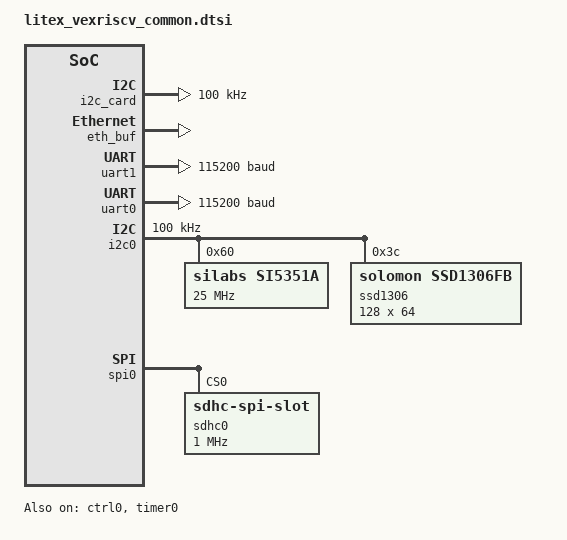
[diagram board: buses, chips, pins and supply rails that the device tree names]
/*
 * AES67 LiteX VexRiscv — common device-tree fragment.
 *
 * Shared across all `litex_vexriscv_<target>` board variants. Contains the
 * hand-written peripheral definitions (I2C devices, UART1 for the display
 * controller, SPI/SDHC, eth_buf IRQ dispatch node, disables, chosen) that
 * are identical for every target. Per-target register addresses live in
 * the auto-generated `<target>_csr.dtsi`, which the variant's `.dts`
 * includes alongside this file.
 */

#include <zephyr/dt-bindings/i2c/i2c.h>

/ {
	chosen {
		zephyr,console = &uart0;
		zephyr,shell-uart = &uart0;
		zephyr,sram = &ram0;
	};
};

/* ---- SoC controller (ctrl) ---- */
&ctrl0 {
	reg-names = "reset",
		    "scratch",
		    "bus_errors";
	status = "okay";
};

/* ---- UART 0 (console) ---- */
&uart0 {
	reg-names = "rxtx",
		    "txfull",
		    "rxempty",
		    "ev_status",
		    "ev_pending",
		    "ev_enable",
		    "txempty",
		    "rxfull";
	interrupts = <0 1>;
	current-speed = <115200>;
	status = "okay";
};

/* ---- Timer 0 ---- */
&timer0 {
	reg-names = "load",
		    "reload",
		    "en",
		    "update_value",
		    "value",
		    "ev_status",
		    "ev_pending",
		    "ev_enable",
		    "uptime_latch",
		    "uptime_cycles";
	interrupts = <1 1>;
	status = "okay";
};

/* ---- I2C 0: Display (SSD1306) + PLL (Si5351A) ---- */
&i2c0 {
	reg-names = "write", "read";
	clock-frequency = <I2C_BITRATE_STANDARD>;
	status = "okay";

	si5351a: si5351a@60 {
		compatible = "silabs,si5351a";
		reg = <0x60>;
		clock-frequency = <25000000>;
		silabs,xtal-load-pf = <10>;
	};

	ssd1306: ssd1306@3c {
		compatible = "solomon,ssd1306fb";
		reg = <0x3c>;
		width = <128>;
		height = <64>;
		segment-offset = <0>;
		page-offset = <0>;
		display-offset = <0>;
		multiplex-ratio = <63>;
		segment-remap;
		com-invdir;
		prechargep = <0x22>;
	};
};

/* ---- I2C 1 (litex,litei2c): disable the default DTSI instance ---- */
&i2c1 {
	status = "disabled";
};

/* Hardware I2C for the AD/DA card controller. Reg addresses come from
 * <target>_csr.dtsi via a &i2c_card override there. */
/ {
	soc {
		i2c_card: i2c2: i2c@f0002800 {
			compatible = "litex,litei2c";
			reg-names = "phy_speed_mode",
				    "master_active",
				    "master_settings",
				    "master_addr",
				    "master_rxtx",
				    "master_status";
			clock-frequency = <I2C_BITRATE_STANDARD>;
			#address-cells = <1>;
			#size-cells = <0>;
			status = "okay";
		};
	};
};

/* ---- SPI 0: SD card ---- */
&spi0 {
	reg-names = "control",
		    "status",
		    "mosi",
		    "miso",
		    "cs",
		    "loopback";
	status = "okay";
	#address-cells = <1>;
	#size-cells = <0>;

	sdhc0: sdhc@0 {
		compatible = "zephyr,sdhc-spi-slot";
		reg = <0>;
		status = "okay";
		spi-max-frequency = <1000000>;
		power-delay-ms = <1000>;
		mmc {
			compatible = "zephyr,sdmmc-disk";
			disk-name = "SD";
			status = "okay";
		};
	};
};

/* ---- EthPacketBuffer EventManager (IRQ dispatch node) ----
 * The eth_buf peripheral is instantiated in C (not DT-bound) but the LiteX
 * interrupt controller dispatches IRQs only for DT nodes picked up by
 * DT_FOREACH_STATUS_OKAY_NODE. Without this node IRQ 3 would storm. */
/ {
	soc {
		eth_buf: eth_buf@f0001000 {
			compatible = "litex,eth-buf-event";
			reg = <0xf0001000 0x20>;
			interrupt-parent = <&intc0>;
			interrupts = <3 1>;
			status = "okay";
		};
	};
};

/* ---- Peripherals absent from our SoC ---- */
&eth0     { status = "disabled"; };
&mdio0    { status = "disabled"; };
&dna0     { status = "disabled"; };
&prbs0    { status = "disabled"; };
&wdt0     { status = "disabled"; };
&clock0   { status = "disabled"; };
&gpio_out { status = "disabled"; };
&gpio_in  { status = "disabled"; };
&i2s_rx   { status = "disabled"; };
&i2s_tx   { status = "disabled"; };
&spi1     { status = "disabled"; };
&pwm0     { status = "disabled"; };

/* ---- Chosen display ---- */
/ {
	chosen {
		zephyr,display = &ssd1306;
	};
};

/* ---- UART 1: display-controller LED UART. Reg override in <target>_csr.dtsi ---- */
/ {
	soc {
		uart1: serial@f0006000 {
			compatible = "litex,uart";
			interrupt-parent = <&intc0>;
			interrupts = <2 1>;
			reg-names = "rxtx",
				    "txfull",
				    "rxempty",
				    "ev_status",
				    "ev_pending",
				    "ev_enable",
				    "txempty",
				    "rxfull";
			current-speed = <115200>;
			status = "okay";
		};
	};

	aliases {
		display-ctrl-uart = &uart1;
	};
};
